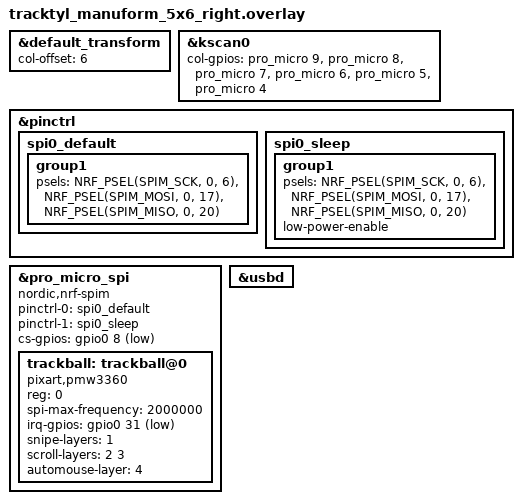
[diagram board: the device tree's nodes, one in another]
#include "tracktyl_manuform_5x6.dtsi"

&default_transform { // The matrix transform for this board is 6 columns over because the left half is 6 columns wide according to the matrix.
    col-offset = <6>;
};

&kscan0 {
    col-gpios
        = <&pro_micro 9 GPIO_ACTIVE_HIGH>
        , <&pro_micro 8 GPIO_ACTIVE_HIGH>
        , <&pro_micro 7 GPIO_ACTIVE_HIGH>
        , <&pro_micro 6 GPIO_ACTIVE_HIGH>
        , <&pro_micro 5 GPIO_ACTIVE_HIGH>
        , <&pro_micro 4 GPIO_ACTIVE_HIGH>
        ;
};

&pinctrl {
    spi0_default: spi0_default {
        group1 {
            psels = <NRF_PSEL(SPIM_SCK, 0, 6)>,
                <NRF_PSEL(SPIM_MOSI, 0, 17)>,
                <NRF_PSEL(SPIM_MISO, 0, 20)>;
        };
    };

    spi0_sleep: spi0_sleep {
        group1 {
            psels = <NRF_PSEL(SPIM_SCK, 0, 6)>,
                <NRF_PSEL(SPIM_MOSI, 0, 17)>,
                <NRF_PSEL(SPIM_MISO, 0, 20)>;
            low-power-enable;
        };
    };
};

&pro_micro_spi {
    status = "okay";
    compatible = "nordic,nrf-spim";
    pinctrl-0 = <&spi0_default>;
    pinctrl-1 = <&spi0_sleep>;
    pinctrl-names = "default", "sleep";
    cs-gpios = <&gpio0 8 GPIO_ACTIVE_LOW>;

    trackball: trackball@0 {
        status = "okay";
        compatible = "pixart,pmw3360";
        reg = <0>;
        spi-max-frequency = <2000000>;
        irq-gpios = <&gpio0 31 (GPIO_ACTIVE_LOW | GPIO_PULL_UP)>;

        /*   optional features   */
        snipe-layers = <1>;
        scroll-layers = <2 3>;
        automouse-layer = <4>;
    };
};

zephyr_udc0: &usbd {
    status = "okay";
};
